# YTM32B1HA0 register map
Vendor: YTMicro; File version: 1.0
CPU: little endian, MPU, FPU, 2 interrupt priority bits
Registers are 32-bit, read-write, reset 0x0 unless marked. A register's access mark holds for its fields unless they carry their own. Offsets are from the block's base; [hi:lo] are bit positions; {n}, {i} and the like mark numbered series; 'fields as' and 'values as' point back to an identical list; <NAME> marks a mode.

## ENET (part 6 of 10) — Ethernet Quality-of-Service
Base 0x401E4000; register names take the prefix ENET_
0x834 RXUDP_ERROR_PACKETS ro — This register provides the number of good IP datagrams received by DWC_ether_qos whose UDP payload has a checksum error.
  [15:0] RXUDPERRPKT rw — This field indicates the number of good IP datagrams received whose UDP payload has a checksum error.
0x838 RXTCP_GOOD_PACKETS ro — This register provides the number of good IP datagrams received by DWC_ether_qos with a good TCP payload.
  [15:0] RXTCPGDPKT rw — This field indicates the number of good IP datagrams received with a good TCP payload.
0x83C RXTCP_ERROR_PACKETS ro — This register provides the number of good IP datagrams received by DWC_ether_qos whose TCP payload has a checksum error.
  [15:0] RXTCPERRPKT rw — This field indicates the number of good IP datagrams received whose TCP payload has a checksum error.
0x840 RXICMP_GOOD_PACKETS ro — This register provides the number of good IP datagrams received by DWC_ether_qos with a good ICMP payload.
  [15:0] RXICMPGDPKT rw — This field indicates the number of good IP datagrams received with a good ICMP payload.
0x844 RXICMP_ERROR_PACKETS ro — This register provides the number of good IP datagrams received by DWC_ether_qos whose ICMP payload has a checksum error.
  [15:0] RXICMPERRPKT rw — This field indicates the number of good IP datagrams received whose ICMP payload has a checksum error.
0x850 RXIPV4_GOOD_OCTETS ro — This register provides the number of bytes received by DWC_ether_qos in good IPv4 datagrams encapsulating TCP, UDP, or ICMP data. (Ethernet header, FCS, pad, or IP pad bytes are not included in this counter.
  [31:0] RXIPV4GDOCT rw — This field indicates the number of bytes received in good IPv4 datagrams encapsulating TCP, UDP, or ICMP data. (Ethernet header, FCS, pad, or IP pad bytes are not included in this counter.
0x854 RXIPV4_HEADER_ERROR_OCTETS ro — This register provides the number of bytes received by DWC_ether_qos in IPv4 data- grams with header errors (checksum, length, version mismatch). The value in the Length field of IPv4 header is used to update this counter. (Ethernet header, FCS, pad, or IP pad bytes are not included in this counter.
  [31:0] RXIPV4HDRERROCT rw — This field indicates the number of bytes received in IPv4 datagrams with header errors (checksum, length, version mismatch). The value in the Length field of IPv4 header is used to update this counter. (Ethernet header, FCS, pad, or IP pad bytes are not included in this counter.
0x858 RXIPV4_NOPAYLOAD_OCTETS ro — This register provides the number of bytes received by DWC_ether_qos in IPv4 data- grams that did not have a TCP, UDP, or ICMP payload. The value in the Length field of IPv4 header is used to update this counter. (Ethernet header, FCS, pad, or IP pad bytes are not included in this counter.
  [31:0] RXIPV4NOPAYOCT rw — This field indicates the number of bytes received in IPv4 datagrams that did not have a TCP, UDP, or ICMP payload. The value in the Length field of IPv4 header is used to update this counter. (Ethernet header, FCS, pad, or IP pad bytes are not included in this counter.
0x85C RXIPV4_FRAGMENTED_OCTETS ro — This register provides the number of bytes received by DWC_ether_qos in IPv4 data- grams that were fragmented. The value in the Length field of IPv4 header is used to update this counter. (Ethernet header, FCS, pad, or IP pad bytes are not included in this counter.
  [31:0] RXIPV4FRAGOCT rw — This field indicates the number of bytes received in IPv4 datagrams that were fragmented. The value in the Length field of IPv4 header is used to update this counter. (Ethernet header, FCS, pad, or IP pad bytes are not included in this counter.
0x860 RXIPV4_UDP_CHECKSUM_DISABLE_OCTETS ro — This register provides the number of bytes received by DWC_ether_qos in a UDP segment that had the UDP checksum disabled. This counter does not count IP Header bytes. (Ethernet header, FCS, pad, or IP pad bytes are not included in this counter.
  [31:0] RXIPV4UDSBLOCT rw — This field indicates the number of bytes received in a UDP segment that had the UDP checksum disabled. This counter does not count IP Header bytes. (Ethernet header, FCS, pad, or IP pad bytes are not included in this counter.
0x864 RXIPV6_GOOD_OCTETS ro — This register provides the number of bytes received by DWC_ether_qos in good IPv6 datagrams encapsulating TCP, UDP, or ICMP data. (Ethernet header, FCS, pad, or IP pad bytes are not included in this counter.
  [31:0] RXIPV6GDOCT rw — This field indicates the number of bytes received in good IPv6 datagrams encapsulating TCP, UDP, or ICMP data. (Ethernet header, FCS, pad, or IP pad bytes are not included in this counter.
0x868 RXIPV6_HEADER_ERROR_OCTETS ro — This register provides the number of bytes received by DWC_ether_qos in IPv6 data- grams with header errors (length, version mismatch). The value in the Length field of IPv6 header is used to update this counter. (Ethernet header, FCS, pad, or IP pad bytes are not included in this counter.
  [31:0] RXIPV6HDRERROCT rw — This field indicates the number of bytes received in IPv6 datagrams with header errors (length, version mismatch). The value in the Length field of IPv6 header is used to update this counter. (Ethernet header, FCS, pad, or IP pad bytes are not included in this counter.
0x86C RXIPV6_NO_PAYLOAD_OCTETS ro — This register provides the number of bytes received by DWC_ether_qos in IPv6 data- grams that did not have a TCP, UDP, or ICMP payload. The value in the Length field of IPv6 header is used to update this counter. (Ethernet header, FCS, pad, or IP pad bytes are not included in this counter.
  [31:0] RXIPV6NOPAYOCT rw — This field indicates the number of bytes received in IPv6 datagrams that did not have a TCP, UDP, or ICMP payload. The value in the Length field of IPv6 header is used to update this counter. (Ethernet header, FCS, pad, or IP pad bytes are not included in this counter.
0x870 RXUDP_GOOD_OCTETS ro — This register provides the number of bytes received by DWC_ether_qos in a good UDP segment. This counter does not count IP header bytes.
  [31:0] RXUDPGDOCT rw — This field indicates the number of bytes received in a good UDP segment. This counter does not count IP header bytes.
0x874 RXUDP_ERROR_OCTETS ro — This register provides the number of bytes received by DWC_ether_qos in a UDP segment that had checksum errors. This counter does not count IP header bytes.
  [31:0] RXUDPERROCT rw — This field indicates the number of bytes received in a UDP segment that had checksum errors. This counter does not count IP header bytes.
0x878 RXTCP_GOOD_OCTETS ro — This register provides the number of bytes received by DWC_ether_qos in a good TCP segment. This counter does not count IP header bytes.
  [31:0] RXTCPGDOCT rw — This field indicates the number of bytes received in a good TCP segment. This counter does not count IP header bytes.
0x87C RXTCP_ERROR_OCTETS ro — This register provides the number of bytes received by DWC_ether_qos in a TCP segment that had checksum errors. This counter does not count IP header bytes.
  [31:0] RXTCPERROCT rw — This field indicates the number of bytes received in a TCP segment that had checksum errors. This counter does not count IP header bytes.
0x880 RXICMP_GOOD_OCTETS ro — This register provides the number of bytes received by DWC_ether_qos in a good ICMP segment. This counter does not count IP header bytes.
  [31:0] RXICMPGDOCT rw — This field indicates the number of bytes received in a good ICMP segment. This counter does not count IP header bytes.
0x884 RXICMP_ERROR_OCTETS ro — This register provides the number of bytes received by DWC_ether_qos in a ICMP segment that had checksum errors. This counter does not count IP header bytes.
  [31:0] RXICMPERROCT rw — This field indicates the number of bytes received in a ICMP segment that had checksum errors. This counter does not count IP header bytes.
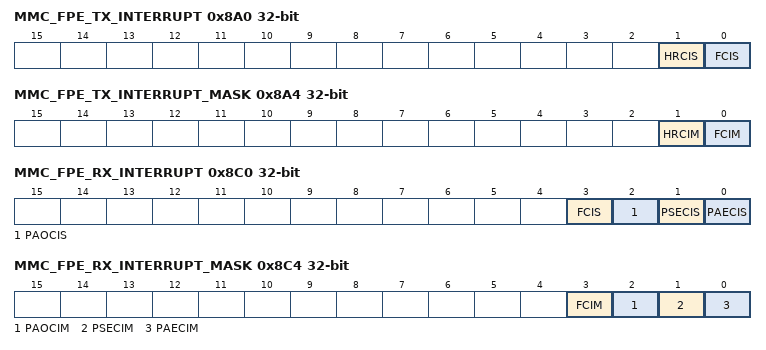
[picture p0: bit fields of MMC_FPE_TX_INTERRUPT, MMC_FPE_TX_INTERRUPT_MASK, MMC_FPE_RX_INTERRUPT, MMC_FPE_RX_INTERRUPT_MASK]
0x8A0 MMC_FPE_TX_INTERRUPT ro — This register maintains the interrupts generated from all FPE related Transmit statistics counters. The MMC FPE Transmit Interrupt register maintains the interrupts generated when transmit statistic counters reach half their maximum values (0x8000_0000 for 32 bit counter and 0x8000 for 16 bit counter), and when they cross their maximum values (0xFFFF_FFFF for 32-bit counter and 0xFFFF for 16-bit counter). When Counter Stop Rollover is set, the interrupts are set but the counter remains at all-ones. The MMC FPE Transmit Interrupt register is a 32 bit register. An interrupt bit is cleared when the respective MMC counter that caused the interrupt is read. The least significant byte lane (Bits[7:0]) of the respective counter must be read to clear the interrupt bit.
  [1] HRCIS rw — This bit is set when the Tx_Hold_Req_Cntr counter reaches half of the maximum value or the maximum value. Access restriction applies. Clears on read. Self-set to 1 on internal event. Exists when any one of the RX/TX MMC counters are enabled during FPE with AV_EST Enabled configuration.
    0=MMC Tx Hold Request Counter Interrupt Status not detected; 1=MMC Tx Hold Request Counter Interrupt Status detected
  [0] FCIS rw — This bit is set when the Tx_FPE_Fragment_Cntr counter reaches half of the maximum value or the maximum value. Access restriction applies. Clears on read. Self-set to 1 on internal event. Exists when any one of the RX/TX MMC counters are enabled during FPE Enabled configuration.
    0=MMC Tx FPE Fragment Counter Interrupt status not detected; 1=MMC Tx FPE Fragment Counter Interrupt status detected
0x8A4 MMC_FPE_TX_INTERRUPT_MASK — This register maintains the masks for interrupts generated from all FPE related Transmit statistics counters. The MMC Receive Interrupt Mask register maintains the masks for the interrupts generated when FPE related receive statistic counters reach half of their maximum value or the maximum values. This register is 32 bit wide.
  [1] HRCIM — Setting this bit masks the interrupt when the Tx_Hold_Req_Cntr counter reaches half of the maximum value or the maximum value. Exists when any one of the RX/TX MMC counters are enabled during FPE with AV_EST Enabled configuration.
    0=MMC Transmit Hold Request Counter Interrupt Mask is disabled; 1=MMC Transmit Hold Request Counter Interrupt Mask is enabled
  [0] FCIM — Setting this bit masks the interrupt when the Tx_FPE_Fragment_Cntr counter reaches half of the maximum value or the maximum value. Exists when any one of the RX/TX MMC counters are enabled during FPE Enabled configuration.
    0=MMC Transmit Fragment Counter Interrupt Mask is disabled; 1=MMC Transmit Fragment Counter Interrupt Mask is enabled
0x8A8 MMC_TX_FPE_FRAGMENT_CNTR — This register provides the number of additional mPackets transmitted due to preemption.
  [31:0] TXFFC — This field indicates the number of additional mPackets that has been transmitted due to preemption Exists when any one of the RX/TX MMC counters are enabled during FPE Enabled configuration.
0x8AC MMC_TX_HOLD_REQ_CNTR — This register provides the count of number of times a hold request is given to MAC
  [31:0] TXHRC — This field indicates count of number of a hold request is given to MAC. Exists when any one of the RX/TX MMC counters are enabled during FPE with AV_EST Enabled configuration.
0x8C0 MMC_FPE_RX_INTERRUPT ro — This register maintains the interrupts generated from all FPE related Receive statistics counters. The MMC FPE Receive Interrupt register maintains the interrupts generated when transmit statistic counters reach half their maximum values (0x8000_0000 for 32 bit counter and 0x8000 for 16 bit counter), and when they cross their maximum values (0xFFFF_FFFF for 32-bit counter and 0xFFFF for 16-bit counter). When Counter Stop Rollover is set, the interrupts are set but the counter remains at all-ones. The MMC FPE Receive Interrupt register is a 32 bit register. An interrupt bit is cleared when the respective MMC counter that caused the interrupt is read. The least significant byte lane (Bits[7:0]) of the respective counter must be read to clear the interrupt bit.
  [3] FCIS rw — This bit is set when the Rx_FPE_Fragment_Cntr counter reaches half of the maximum value or the maximum value. Access restriction applies. Clears on read. Self-set to 1 on internal event. Exists when any one of the RX/TX MMC counters are enabled during FPE Enabled configuration.
    0=MMC Rx FPE Fragment Counter Interrupt Status not detected; 1=MMC Rx Hold Request Counter Interrupt Status detected
  [2] PAOCIS rw — This bit is set when the Rx_Packet_Assemble_Ok_Cntr counter reaches half of the maximum value or the maximum value. Access restriction applies. Clears on read. Self-set to 1 on internal event. Exists when any one of the RX/TX MMC counters are enabled during FPE Enabled configuration.
    0=MMC Rx Packet Assembly OK Counter Interrupt Status not detected; 1=MMC Rx Packet Assembly OK Counter Interrupt Status detected
  [1] PSECIS rw — This bit is set when the Rx_Packet_SMD_Err_Cntr counter reaches half of the maximum value or the maximum value. Access restriction applies. Clears on read. Self-set to 1 on internal event. Exists when any one of the RX/TX MMC counters are enabled during FPE Enabled configuration.
    0=MMC Rx Packet SMD Error Counter Interrupt Status not detected; 1=MMC Rx Packet SMD Error Counter Interrupt Status detected
  [0] PAECIS rw — This bit is set when the Rx_Packet_Assemble_Err_Cntr counter reaches half of the maximum value or the maximum value. Access restriction applies. Clears on read. Self-set to 1 on internal event. Exists when any one of the RX/TX MMC counters are enabled during FPE Enabled configuration.
    0=MMC Rx Packet Assembly Error Counter Interrupt Status not detected; 1=MMC Rx Packet Assembly Error Counter Interrupt Status detected
0x8C4 MMC_FPE_RX_INTERRUPT_MASK — This register maintains the masks for interrupts generated from all FPE related Receive statistics counters. The MMC Receive Interrupt Mask register maintains the masks for the interrupts generated when FPE related receive statistic counters reach half of their maximum value or the maximum values. This register is 32 bit wide.
  [3] FCIM — Setting this bit masks the interrupt when the Rx_FPE_Fragment_Cntr counter reaches half of the maximum value or the maximum value. Exists when any one of the RX/TX MMC counters are enabled during FPE Enabled configuration.
    0=MMC Rx FPE Fragment Counter Interrupt Mask is disabled; 1=MMC Rx FPE Fragment Counter Interrupt Mask is enabled
  [2] PAOCIM — Setting this bit masks the interrupt when the Rx_Packet_Assemble_Ok_Cntr counter reaches half of the maximum value or the maximum value. Exists when any one of the RX/TX MMC counters are enabled during FPE Enabled configuration.
    0=MMC Rx Packet Assembly OK Counter Interrupt Mask is disabled; 1=MMC Rx Packet Assembly OK Counter Interrupt Mask is enabled
  [1] PSECIM — Setting this bit masks the interrupt when the Rx_Packet_SMD_Err_Cntr counter reaches half of the maximum value or the maximum value. Exists when any one of the RX/TX MMC counters are enabled during FPE Enabled configuration.
    0=MMC Rx Packet SMD Error Counter Interrupt Mask is disabled; 1=MMC Rx Packet SMD Error Counter Interrupt Mask is enabled
  [0] PAECIM — Setting this bit masks the interrupt when the Rx_Packet_Assemble_Err_Cntr counter reaches half of the maximum value or the maximum value. Exists when any one of the RX/TX MMC counters are enabled during FPE Enabled configuration.
    0=MMC Rx Packet Assembly Error Counter Interrupt Mask is disabled; 1=MMC Rx Packet Assembly Error Counter Interrupt Mask is enabled
0x8C8 MMC_RX_PACKET_ASSEMBLY_ERR_CNTR ro — This register provides the number of MAC frames with reassembly errors on the Receiver, due to mismatch in the Fragment Count value.
  [31:0] PAEC rw — This field indicates the number of MAC frames with reassembly errors on the Receiver, due to mismatch in the Fragment Count value. Exists when any one of the RX/TX MMC counters are enabled during FPE Enabled configuration.
0x8CC MMC_RX_PACKET_SMD_ERR_CNTR ro — This register provides the number of received MAC frames rejected due to unknown SMD value and MAC frame fragments rejected due to arriving with an SMD-C when there was no preceding preempted frame.
  [31:0] PSEC rw — This field indicates the number of MAC frames rejected due to unknown SMD value and MAC frame fragments rejected due to arriving with an SMD-C when there was no preceding preempted frame. Exists when at least one of the RX/TX MMC counters are enabled during FPE Enabled configuration.
0x8D0 MMC_RX_PACKET_ASSEMBLY_OK_CNTR ro — This register provides the number of MAC frames successfully reassembled by the Receiver.
  [31:0] PAOC rw — This field indicates the number of MAC frames successfully reassembled by the Receiver. Exists when at least one of the RX/TX MMC counters are enabled during FPE Enabled configuration.
0x8D4 MMC_RX_FPE_FRAGMENT_CNTR ro — This register provides the number of MAC frame fragments received by the Receiver.
  [31:0] FFC rw — This field indicates the number of MAC frame fragments received by the Receiver. Exists when at least one of the RX/TX MMC counters are enabled during FPE Enabled configuration.
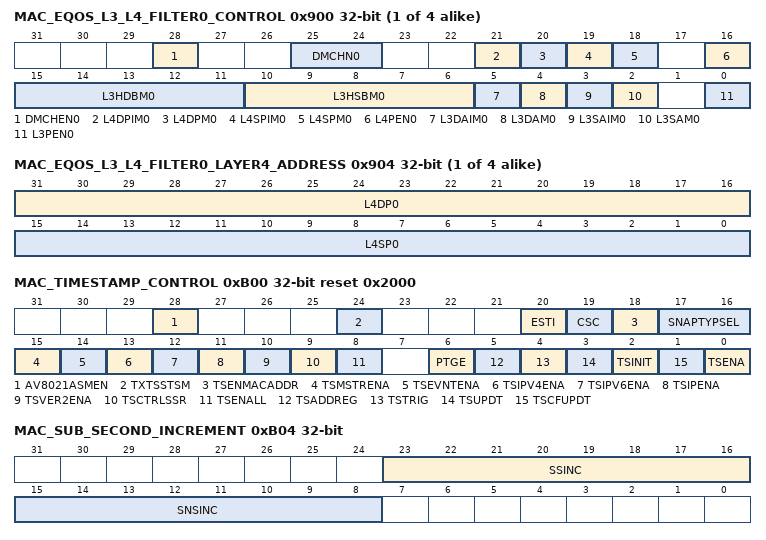
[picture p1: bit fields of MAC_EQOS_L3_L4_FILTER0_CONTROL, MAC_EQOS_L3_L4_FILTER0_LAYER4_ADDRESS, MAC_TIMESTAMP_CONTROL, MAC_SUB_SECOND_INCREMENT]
{0x900+0x30*i} MAC_EQOS_L3_L4_FILTER{i}_CONTROL (i=0..3) — The Layer 3 and Layer 4 Control register controls the operations of filter 0 of Layer 3 and Layer 4.
  [28] DMCHEN0 — When set, this bit enables the selection of the DMA channel number for the packet that is passed by this L3_L4 filter. The DMA channel is indicated by the DMCHN bits. When this bit is reset, the DMA channel is not decided by this filter.
    0=DMA Channel Select is disabled; 1=DMA Channel Select is enabled
  [25:24] DMCHN0 — When DMCHEN is set high, this field selects the DMA Channel number to which the packet passed by this filter is routed. The width of this field depends on the number of the DMA channels present in your configuration.
  [21] L4DPIM0 — When this bit is set, the Layer 4 Destination Port number field is enabled for inverse matching. When this bit is reset, the Layer 4 Destination Port number field is enabled for perfect matching. This bit is valid and applicable only when the L4DPM0 bit is set high.
    0=Layer 4 Destination Port Inverse Match is disabled; 1=Layer 4 Destination Port Inverse Match is enabled
  [20] L4DPM0 — When this bit is set, the Layer 4 Destination Port number field is enabled for matching. When this bit is reset, the MAC ignores the Layer 4 Destination Port number field for matching.
    0=Layer 4 Destination Port Match is disabled; 1=Layer 4 Destination Port Match is enabled
  [19] L4SPIM0 — When this bit is set, the Layer 4 Source Port number field is enabled for inverse matching. When this bit is reset, the Layer 4 Source Port number field is enabled for perfect matching. This bit is valid and applicable only when the L4SPM0 bit is set high.
    0=Layer 4 Source Port Inverse Match is disabled; 1=Layer 4 Source Port Inverse Match is enabled
  [18] L4SPM0 — When this bit is set, the Layer 4 Source Port number field is enabled for matching. When this bit is reset, the MAC ignores the Layer 4 Source Port number field for matching.
    0=Layer 4 Source Port Match is disabled; 1=Layer 4 Source Port Match is enabled
  [16] L4PEN0 — When this bit is set, the Source and Destination Port number fields of UDP packets are used for matching. When this bit is reset, the Source and Destination Port number fields of TCP packets are used for matching. The Layer 4 matching is done only when the L4SPM0 or L4DPM0 bit is set.
    0=Layer 4 Protocol Match is disabled; 1=Layer 4 Protocol Match is enabled
  [15:11] L3HDBM0 — IPv4 Packets: This field contains the number of higher bits of IP Destination Address that are matched in the IPv4 packets. The following list describes the values of this field: ■ 0: No bits are masked. ■ 1: LSb[0] is masked ■ 2: Two LSbs [1:0] are masked ■ .. ■ 31: All bits except MSb are masked. IPv6 Packets: Bits[12:11] of this field correspond to Bits[6:5] of L3HSBM0 which indicate the number of lower bits of IP Source or Destination Address that are masked in the IPv6 packets. The following list describes the concatenated values of the L3HDBM0[1:0] and L3HSBM0 bits: ■ 0: No bits are masked. ■ 1: LSb[0] is masked. ■ 2: Two LSbs [1:0] are masked ■ .. ■ 127: All bits except MSb are masked. This field is valid and applicable only when the L3DAM0 or L3SAM0 bit is set.
  [10:6] L3HSBM0 — IPv4 Packets: This field contains the number of lower bits of IP Source Address that are masked for matching in the IPv4 packets. The following list describes the values of this field: ■ 0: No bits are masked. ■ 1: LSb[0] is masked ■ 2: Two LSbs [1:0] are masked ■ .. ■ 31: All bits except MSb are masked. IPv6 Packets: This field contains Bits[4:0] of L3HSBM0. These bits indicate the number of higher bits of IP Source or Destination Address matched in the IPv6 packets. This field is valid and applicable only when the L3DAM0 or L3SAM0 bit is set high.
  [5] L3DAIM0 — When this bit is set, the Layer 3 IP Destination Address field is enabled for inverse matching. When this bit is reset, the Layer 3 IP Destination Address field is enabled for perfect matching. This bit is valid and applicable only when the L3DAM0 bit is set high.
    0=Layer 3 IP DA Inverse Match is disabled; 1=Layer 3 IP DA Inverse Match is enabled
  [4] L3DAM0 — When this bit is set, the Layer 3 IP Destination Address field is enabled for matching. When this bit is reset, the MAC ignores the Layer 3 IP Destination Address field for matching.
    0=Layer 3 IP DA Match is disabled; 1=Layer 3 IP DA Match is enabled
  [3] L3SAIM0 — When this bit is set, the Layer 3 IP Source Address field is enabled for inverse matching. When this bit reset, the Layer 3 IP Source Address field is enabled for perfect matching. This bit is valid and applicable only when the L3SAM0 bit is set.
    0=Layer 3 IP SA Inverse Match is disabled; 1=Layer 3 IP SA Inverse Match is enabled
  [2] L3SAM0 — When this bit is set, the Layer 3 IP Source Address field is enabled for matching. When this bit is reset, the MAC ignores the Layer 3 IP Source Address field for matching. Note: When the L3PEN0 bit is set, you should set either this bit or the L3DAM0 bit because either IPv6 SA or DA can be checked for filtering.
    0=Layer 3 IP SA Match is disabled; 1=Layer 3 IP SA Match is enabled
  [0] L3PEN0 — When this bit is set, the Layer 3 IP Source or Destination Address matching is enabled for IPv6 packets. When this bit is reset, the Layer 3 IP Source or Destination Address matching is enabled for IPv4 packets. The Layer 3 matching is done only when the L3SAM0 or L3DAM0 bit is set.
    0=Layer 3 Protocol Match is disabled; 1=Layer 3 Protocol Match is enabled
{0x904+0x30*i} MAC_EQOS_L3_L4_FILTER{i}_LAYER4_ADDRESS (i=0..3) — The MAC_Layer4_Address(n), MAC_L3_L4_Control(n), MAC_Layer3_Addr0_Reg(n), MAC_Layer3_Addr1_Reg(n), MAC_Layer3_Addr2_Reg(n) and MAC_Layer3_Addr3_Reg(n) registers are reserved (RO with default value) if Enable Layer 3 and Layer 4 Packet Filter option is not selected while configuring the core. You can configure the Layer 3 and Layer 4 Address Registers to be double-synchronized by selecting the Synchronize Layer 3 and Layer 4 Address Registers to Rx Clock Domain option while configuring the core. When you select this option, the synchronization is triggered only when Bits[31:24] (in little-endian mode) or Bits[7:0] (in big-endian mode) of the Layer 3 and Layer 4 Address Registers are written. For proper synchronization updates, you should perform consecutive writes to same Layer 3 and Layer 4 Address Registers after at least four clock cycles delay of the destination clock.
  [31:16] L4DP0 — When the L4PEN0 bit is reset and the L4DPM0 bit is set in the MAC_L3_L4_Control0 register, this field contains the value to be matched with the TCP Destination Port Number field in the IPv4 or IPv6 packets. When the L4PEN0 and L4DPM0 bits are set in MAC_L3_L4_Control0 register, this field contains the value to be matched with the UDP Destination Port Number field in the IPv4 or IPv6 packets.
  [15:0] L4SP0 — When the L4PEN0 bit is reset and the L4SPM0 bit is set in the MAC_L3_L4_Control0 register, this field contains the value to be matched with the TCP Source Port Number field in the IPv4 or IPv6 packets. When the L4PEN0 and L4SPM0 bits are set in MAC_L3_L4_Control0 register, this field contains the value to be matched with the UDP Source Port Number field in the IPv4 or IPv6 packets.
0x910 MAC_EQOS_L3_L4_FILTER{i}_LAYER3_ADDR0 (i=0..3) — For IPv4 packets, the Layer 3 Address 0 Register 0 register contains the 32-bit IP Source Address field. For IPv6 packets, it contains Bits[31:0] of the 128-bit IP Source Address or Destination Address field.
  [31:0] L3A — When the L3PEN0 and L3SAM0 bits are set in the MAC_L3_L4_Control0 register, this field contains the value to be matched with Bits[31:0] of the IP Source Address field in the IPv6 packets. When the L3PEN0 and L3DAM0 bits are set in the MAC_L3_L4_Control0 register, this field contains the value to be matched with Bits[31:0] of the IP Destination Address field in the IPv6 packets. When the L3PEN0 bit is reset and the L3SAM0 bit is set in the MAC_L3_L4_Control0 register, this field contains the value to be matched with the IP Source Address field in the IPv4 packets.
0x914 MAC_EQOS_L3_L4_FILTER{i}_LAYER3_ADDR1 (i=0..3) — For IPv4 packets, the Layer 3 Address 0 Register 0 register contains the 32-bit IP Source Address field. For IPv6 packets, it contains Bits[31:0] of the 128-bit IP Source Address or Destination Address field.
  fields as MAC_EQOS_L3_L4_FILTER0_LAYER3_ADDR0
0x918 MAC_EQOS_L3_L4_FILTER{i}_LAYER3_ADDR2 (i=0..3) — For IPv4 packets, the Layer 3 Address 0 Register 0 register contains the 32-bit IP Source Address field. For IPv6 packets, it contains Bits[31:0] of the 128-bit IP Source Address or Destination Address field.
  fields as MAC_EQOS_L3_L4_FILTER0_LAYER3_ADDR0
0x91C MAC_EQOS_L3_L4_FILTER{i}_LAYER3_ADDR3 (i=0..3) — For IPv4 packets, the Layer 3 Address 0 Register 0 register contains the 32-bit IP Source Address field. For IPv6 packets, it contains Bits[31:0] of the 128-bit IP Source Address or Destination Address field.
  fields as MAC_EQOS_L3_L4_FILTER0_LAYER3_ADDR0
0xB00 MAC_TIMESTAMP_CONTROL reset 0x2000 — This register controls the operation of the System Time generator and processing of PTP packets for timestamping in the Receiver.
  [28] AV8021ASMEN — When this bit is set, the MAC processes only untagged PTP over Ethernet packets for providing PTP status and capturing timestamp snapshots, that is, IEEE 802.1AS mode of operation. When PTP offload feature is enabled, for the purpose of PTP offload, the transport specific field in the PTP header is generated and checked based on the value of this bit.
    0=AV 802.1AS Mode is disabled; 1=AV 802.1AS Mode is enabled
  [24] TXTSSTSM — When this bit is set, the MAC overwrites the earlier transmit timestamp status even if it is not read by the software. The MAC indicates this by setting the TXTSSMIS bit of the MAC_Tx_Timestamp_Status_Nanoseconds register. When this bit is reset, the MAC ignores the timestamp status of current packet if the timestamp status of previous packet is not read by the software. The MAC indicates this by setting the TXTSSMIS bit of the MAC_Tx_Timestamp_Status_Nanoseconds register.
    0=Transmit Timestamp Status Mode is disabled; 1=Transmit Timestamp Status Mode is enabled
  [20] ESTI — When this bit is set, the MAC uses the external 64-bit reference System Time input for the following: ■ To take the timestamp provided as status ■ To insert the timestamp in transmit PTP packets when One-step Timestamp or Timestamp Offload feature is enabled. When this bit is reset, the MAC uses the internal reference System Time.
    0=External System Time Input is disabled; 1=External System Time Input is enabled
  [19] CSC — When this bit is set, the last two bytes of PTP message sent over UDP/IPv4 is updated to keep the UDP checksum correct, for changes made to origin timestamp and/or correction field as part of one step timestamp operation. The application shall form the packet with these two dummy bytes. When reset, no updates are done to keep the UDP checksum correct. The application shall form the packet with UDP checksum set to 0.
    0=checksum correction during OST for PTP over UDP/IPv4 packets is disabled; 1=checksum correction during OST for PTP over UDP/IPv4 packets is enabled
  [18] TSENMACADDR — When this bit is set, the DA MAC address (that matches any MAC Address register) is used to filter the PTP packets when PTP is directly sent over Ethernet. When this bit is set, received PTP packets with DA containing a special multicast or unicast address that matches the one programmed in MAC address registers are considered for processing as indicated below, when PTP is directly sent over Ethernet. For normal time stamping operation, MAC address registers 0 to 31 is considered for unicast destination address matching. For PTP offload, only MAC address register 0 is considered for unicast destination address matching.
    0=MAC Address for PTP Packet Filtering is disabled; 1=MAC Address for PTP Packet Filtering is enabled
  [17:16] SNAPTYPSEL — These bits, along with Bits 15 and 14, decide the set of PTP packet types for which snapshot needs to be taken. The encoding is given in Timestamp Snapshot Dependency on Register Bits Table.
  [15] TSMSTRENA — When this bit is set, the snapshot is taken only for the messages that are relevant to the master node. Otherwise, the snapshot is taken for the messages relevant to the slave node.
    0=Snapshot for Messages Relevant to Master is disabled; 1=Snapshot for Messages Relevant to Master is enabled
  [14] TSEVNTENA — When this bit is set, the timestamp snapshot is taken only for event messages (SYNC, Delay_Req, Pdelay_Req, or Pdelay_Resp). When this bit is reset, the snapshot is taken for all messages except Announce, Management, and Signaling. For more information about the timestamp snapshots, see Timestamp Snapshot Dependency on Register Bits Table.
    0=Timestamp Snapshot for Event Messages is disabled; 1=Timestamp Snapshot for Event Messages is enabled
  [13] TSIPV4ENA — When this bit is set, the MAC receiver processes the PTP packets encapsulated in IPv4-UDP packets. When this bit is reset, the MAC ignores the PTP transported over IPv4-UDP packets. This bit is set by default.
    0=Processing of PTP Packets Sent over IPv4-UDP is disabled; 1=Processing of PTP Packets Sent over IPv4-UDP is enabled
  [12] TSIPV6ENA — When this bit is set, the MAC receiver processes the PTP packets encapsulated in IPv6-UDP packets. When this bit is clear, the MAC ignores the PTP transported over IPv6-UDP packets.
    0=Processing of PTP Packets Sent over IPv6-UDP is disabled; 1=Processing of PTP Packets Sent over IPv6-UDP is enabled
  [11] TSIPENA — When this bit is set, the MAC receiver processes the PTP packets encapsulated directly in the Ethernet packets. When this bit is reset, the MAC ignores the PTP over Ethernet packets.
    0=Processing of PTP over Ethernet Packets is disabled; 1=Processing of PTP over Ethernet Packets is enabled
  [10] TSVER2ENA — When this bit is set, the IEEE 1588 version 2 format is used to process the PTP packets. When this bit is reset, the IEEE 1588 version 1 format is used to process the PTP packets. The IEEE 1588 formats are described in 'PTP Processing and Control'.
    0=PTP Packet Processing for Version 2 Format is disabled; 1=PTP Packet Processing for Version 2 Format is enabled
  [9] TSCTRLSSR — When this bit is set, the Timestamp Low register rolls over after 0x3B9A_C9FF value (that is, 1 nanosecond accuracy) and increments the timestamp (High) seconds. When this bit is reset, the rollover value of sub-second register is 0x7FFF_FFFF. The sub-second increment must be programmed correctly depending on the PTP reference clock frequency and the value of this bit.
    0=Timestamp Digital or Binary Rollover Control is disabled; 1=Timestamp Digital or Binary Rollover Control is enabled
  [8] TSENALL — When this bit is set, the timestamp snapshot is enabled for all packets received by the MAC.
    0=Timestamp for All Packets disabled; 1=Timestamp for All Packets enabled
  [6] PTGE — When this bit is set the Presentation Time generation will be enabled.
    0=Presentation Time Generation is disabled; 1=Presentation Time Generation is enabled
  [5] TSADDREG — When this bit is set, the content of the Timestamp Addend register is updated in the PTP block for fine correction. This bit is cleared when the update is complete. This bit should be zero before it is set. Access restriction applies. Setting 1 sets. Self-cleared. Setting 0 has no effect.
    0=Addend Register is not updated; 1=Addend Register is updated
  [4] TSTRIG — When this bit is set, the timestamp interrupt is generated when the System Time becomes greater than the value written in the Target Time register. This bit is reset after the Timestamp Trigger Interrupt is generated. Access restriction applies. Setting 1 sets. Self-cleared. Setting 0 has no effect.
    0=Timestamp Interrupt Trigger is not enabled; 1=Timestamp Interrupt Trigger is enabled
  [3] TSUPDT — When this bit is set, the system time is updated (added or subtracted) with the value specified in MAC_System_Time_Seconds_Update and MAC_System_Time_Nanoseconds_Update registers. This bit should be zero before updating it. This bit is reset when the update is complete in hardware. The Timestamp Higher Word register (if enabled during core configuration) is not updated. When Media Clock Generation and Recovery is configured (DWC_EQOS_FLEXI_PPS_OUT_EN) and enabled MAC_Presn_Time_Updt should also be updated before setting this field. Access restriction applies. Setting 1 sets. Self-cleared. Setting 0 has no effect.
    0=Timestamp Update is not enabled; 1=Timestamp Update is enabled
  [2] TSINIT — When this bit is set, the system time is initialized (overwritten) with the value specified in the MAC_System_Time_Seconds_Update and MAC_System_Time_Nanoseconds_Update registers. This bit should be zero before it is updated. This bit is reset when the initialization is complete. The Timestamp Higher Word register (if enabled during core configuration) can only be initialized. When Media Clock Generation and Recovery is configured (DWC_EQOS_FLEXI_PPS_OUT_EN) and enabled MAC_Presn_Time_Updt should also be updated before setting this field. Access restriction applies. Setting 1 sets. Self-cleared. Setting 0 has no effect.
    0=Timestamp is not initialized; 1=Timestamp is initialized
  [1] TSCFUPDT — When this bit is set, the Fine method is used to update system timestamp. When this bit is reset, Coarse method is used to update the system timestamp.
    0=Coarse method is used to update system timestamp; 1=Fine method is used to update system timestamp
  [0] TSENA — When this bit is set, the timestamp is added for Transmit and Receive packets. When disabled, timestamp is not added for transmit and receive packets and the Timestamp Generator is also suspended. You need to initialize the Timestamp (system time) after enabling this mode. On the Receive side, the MAC processes the 1588 packets only if this bit is set.
    0=Timestamp is disabled; 1=Timestamp is enabled
0xB04 MAC_SUB_SECOND_INCREMENT — This register contains the sub-second increment value for the Timestamp Addend register. The value in this register is added to the Timestamp Addend register every 1 second. The value in this register is updated by software.
  [23:16] SSINC — The value programmed in this field is accumulated every clock cycle (of clk_ptp_i) with the contents of the sub-second register. For example, when the PTP clock is 50 MHz (period is 20 ns), you should program 20 (0x14) when the System Time Nanoseconds register has an accuracy of 1 ns [Bit 9 (TSCTRLSSR) is set in MAC_Timestamp_Control]. When TSCTRLSSR is clear, the Nanoseconds register has a resolution of ~0.465 ns. In this case, you should program a value of 43 (0x2B) which is derived by 20 ns/0.465.
  [15:8] SNSINC — This field contains the sub-nanosecond increment value, represented in nanoseconds multiplied by 2^8. This value is accumulated with the sub-nanoseconds field of the subsecond register. For example, when TSCTRLSSR field in the MAC_Timestamp_Control register is set. and if the required increment is 5.3ns, then SSINC should be 0x05 and SNSINC should be 0x4C.
0xB08 MAC_SYSTEM_TIME_SECONDS — The System Time Seconds register, along with System Time Nanoseconds register, indi- cates the current value of the system time maintained by the MAC. Though it is updated on a contin- uous basis, there is some delay from the actual time because of clock domain transfer latencies (from clk_ptp_ref_i to CSR clock).
  [31:0] TSS — The value in this field indicates the current value in seconds of the System Time maintained by the MAC.
0xB0C MAC_SYSTEM_TIME_NANOSECONDS — The System Time Nanoseconds register, along with System Time Seconds register, indi- cates the current value of the system time maintained by the MAC.
  [30:0] TSSS — The value in this field has the sub-second representation of time, with an accuracy of 0.46 ns. When Bit 9 is set in MAC_Timestamp_Control, each bit represents 1 ns. The maximum value is 0x3B9A_C9FF after which it rolls-over to zero.
0xB10 MAC_SYSTEM_TIME_SECONDS_UPDATE — The System Time Seconds Update register, along with the System Time Nanoseconds Update register, initializes or updates the system time maintained by the MAC. You must write both registers before setting the TSINIT or TSUPDT bits in DWC_eqos_top_map/EQOS_MAC/MAC_- Timestamp_Control.
  [31:0] TSS — The value in this field is the seconds part of the update. When ADDSUB is reset, this field must be programmed with the seconds part of the update value. When ADDSUB is set, this field must be programmed with the complement of the seconds part of the update value. For example, if 2.000000001 seconds need to be subtracted from the system time, the TSS field in the MAC_Timestamp_Seconds_Update register must be 0xFFFF_FFFE (that is, 2^32 - 2).
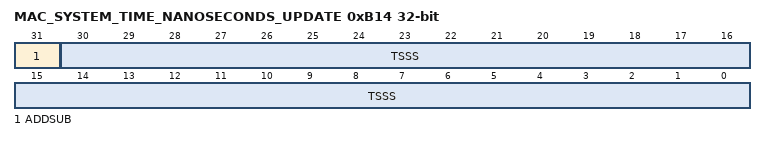
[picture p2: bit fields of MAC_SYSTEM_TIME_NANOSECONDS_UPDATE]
0xB14 MAC_SYSTEM_TIME_NANOSECONDS_UPDATE — The System Time Nanoseconds Update register, along with the System Time Seconds Update register, initializes or updates the system time maintained by the MAC. You must write both registers before setting the TSINIT or TSUPDT bits in DWC_eqos_top_map/EQOS_MAC/MAC_- Timestamp_Control.
  [31] ADDSUB — When this bit is set, the time value is subtracted with the contents of the update register. When this bit is reset, the time value is added with the contents of the update register.
    0=Add time; 1=Subtract time
  [30:0] TSSS — The value in this field is the sub-seconds part of the update. When ADDSUB is reset, this field must be programmed with the sub-seconds part of the update value, with an accuracy based on the TSCTRLSSR bit of the MAC_Timestamp_Control register. When ADDSUB is set, this field must be programmed with the complement of the sub-seconds part of the update value as described below. When TSCTRLSSR bit in MAC_Timestamp_Control is set, the programmed value must be 10^9 - <sub-second value>. When TSCTRLSSR bit in MAC_Timestamp_Control is reset, the programmed value must be 2^31 - <sub-second_value>. When the TSCTRLSSR bit is reset in the MAC_Timestamp_Control register, each bit represents an accuracy of 0.46 ns. When the TSCTRLSSR bit is set in the MAC_Timestamp_Control register, each bit represents 1 ns and the programmed value should not exceed 0x3B9A_C9FF. For example, if 2.000000001 seconds need to be subtracted from the system time, then the TSSS field in the MAC_Timestamp_Nanoseconds_Update register must be 0x7FFF_FFFF (that is, 2^31 - 1), when TSCTRLSSR bit in MAC_Timestamp_Control is reset and 0x3B9A_C9FF (that is, 10^9 - 1), when TSCTRLSSR bit in MAC_Timestamp_Control is set.
0xB18 MAC_TIMESTAMP_ADDEND — Timestamp Addend register. This register value is used only when the system time is configured for Fine Update mode (TSCFUPDT bit in the MAC_Timestamp_Control register). The content of this register is added to a 32-bit accumulator in every clock cycle (of clk_ptp_ref_i) and the system time is updated whenever the accumulator overflows.
  [31:0] TSAR — This field indicates the 32-bit time value to be added to the Accumulator register to achieve time synchronization.
0xB1C MAC_SYSTEM_TIME_HIGHER_WORD_SECONDS
  [15:0] TSHWR — This field contains the most-significant 16-bits of timestamp seconds value. This register is optional. You can add this register by selecting the Add IEEE 1588 Higher Word Register option. This register is directly written to initialize the value and it is incremented when there is an overflow from 32-bits of the System Time Seconds register. Access restriction applies. Updated based on the event. Setting 1 sets. Setting 0 clears.
